# M460 register map
File version: 1.0
Registers are 32-bit, read-write, reset 0x0 unless marked. A register's access mark holds for its fields unless they carry their own. Offsets are from the block's base; [hi:lo] are bit positions.

## SYS (part 2 of 2) — SYS Register Map
Base 0x40000000
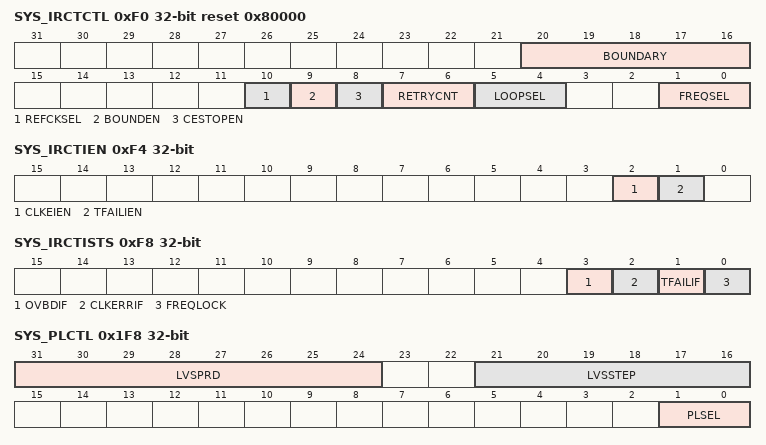
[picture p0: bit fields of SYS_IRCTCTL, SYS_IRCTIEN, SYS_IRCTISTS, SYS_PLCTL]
0xF0 SYS_IRCTCTL reset 0x80000 — HIRC Trim Control Register
  [20:16] BOUNDARY — Boundary Selection. Fill the boundary range from 0x1 to 0x31, 0x0 is reserved. Note: This field is effective only when the BOUNDEN(SYS_IRCTCTL[9]) is enabled.
  [10] REFCKSEL — Reference Clock Selection. Note: HIRC trim reference clock is 20 kHz in test mode.
    0=HIRC trim reference clock is from LXT (32.768 kHz); 1=HIRC trim reference clock is from internal USB synchronous mode
  [9] BOUNDEN — Boundary Enable Bit
    0=Boundary function Disabled; 1=Boundary function Enabled
  [8] CESTOPEN — Clock Error Stop Enable Bit
    0=The trim operation is keep going if clock is inaccuracy; 1=The trim operation is stopped if clock is inaccuracy
  [7:6] RETRYCNT — Trim Value Update Limitation Count. This field defines that how many times the auto trim circuit will try to update the HIRC trim value before the frequency of HIRC locked. Once the HIRC locked, the internal trim value update counter will be reset. If the trim value update counter reached this limitation value and frequency of HIRC still doesn't lock, the auto trim operation will be disabled and FREQSEL will be cleared to 00.
    0=Trim retry count limitation is 64 loops; 1=Trim retry count limitation is 128 loops; 2=Trim retry count limitation is 256 loops; 3=Trim retry count limitation is 512 loops
  [5:4] LOOPSEL — Trim Calculation Loop Selection. This field defines that trim value calculation is based on how many reference clocks. Note: For example, if LOOPSEL is set as 00, auto trim circuit will calculate trim value based on the average frequency difference in 4 clocks of reference clock.
    0=Trim value calculation is based on average difference in 4 clocks of reference clock; 1=Trim value calculation is based on average difference in 8 clocks of reference clock; 2=Trim value calculation is based on average difference in 16 clocks of reference clock; 3=Trim value calculation is based on average difference in 32 clocks of reference clock
  [1:0] FREQSEL — Trim Frequency Selection. This field indicates the target frequency of 12 MHz internal high speed RC oscillator (HIRC) auto trim. During auto trim operation, if clock error detected with CESTOPEN is set to 1 or trim retry limitation count reached, this field will be cleared to 00 automatically.
    0=Disable HIRC auto trim function; 1=Enable HIRC auto trim function and trim HIRC to 12 MHz
0xF4 SYS_IRCTIEN — HIRC Trim Interrupt Enable Register
  [2] CLKEIEN — Clock Error Interrupt Enable Bit. This bit controls if CPU would get an interrupt while clock is inaccuracy during auto trim operation. If this bit is set to1, and CLKERRIF(SYS_IRCTISTS[2]) is set during auto trim operation, an interrupt will be triggered to notify the clock frequency is inaccuracy.
    0=Disable CLKERRIF(SYS_IRCTISTS[2]) status to trigger an interrupt to CPU; 1=Enable CLKERRIF(SYS_IRCTISTS[2]) status to trigger an interrupt to CPU
  [1] TFAILIEN — Trim Failure Interrupt Enable Bit. This bit controls if an interrupt will be triggered while HIRC trim value update limitation count reached and HIRC frequency still not locked on target frequency set by FREQSEL(SYS_IRCTCTL[1:0]). If this bit is high and TFAILIF(SYS_IRCTISTS[1]) is set during auto trim operation, an interrupt will be triggered to notify that HIRC trim value update limitation count was reached.
    0=Disable TFAILIF(SYS_IRCTISTS[1]) status to trigger an interrupt to CPU; 1=Enable TFAILIF(SYS_IRCTISTS[1]) status to trigger an interrupt to CPU
0xF8 SYS_IRCTISTS — HIRC Trim Interrupt Status Register
  [3] OVBDIF — Over Boundary Status. When the over boundary function is set, if there occurs the over boundary condition, this flag will be set. Note: Write 1 to clear this flag.
    0=Over boundary condition did not occur; 1=Over boundary condition occurred
  [2] CLKERRIF — Clock Error Interrupt Status. When the frequency of 32.768 kHz external low speed crystal oscillator (LXT) or 12 MHz internal high speed RC oscillator (HIRC) is shift larger to unreasonable value, this bit will be set and to be an indicate that clock frequency is inaccuracy. Once this bit is set to 1, the auto trim operation stopped and FREQSEL(SYS_IRCTCTL[1:0]) will be cleared to 00 by hardware automatically if CESTOPEN(SYS_IRCTCTL[8]) is set to 1. If this bit is set and CLKEIEN(SYS_IRCTIEN[2]) is high, an interrupt will be triggered to notify the clock frequency is inaccuracy. Write 1 to clear this to 0.
    0=Clock frequency is accuracy; 1=Clock frequency is inaccuracy
  [1] TFAILIF — Trim Failure Interrupt Status. This bit indicates that HIRC trim value update limitation count reached and the HIRC clock frequency still doesn't be locked. Once this bit is set, the auto trim operation stopped and FREQSEL(SYS_IRCTCTL[1:0]) will be cleared to 00 by hardware automatically. If this bit is set and TFAILIEN(SYS_IRCTIEN[1]) is high, an interrupt will be triggered to notify that HIRC trim value update limitation count was reached. Write 1 to clear this to 0.
    0=Trim value update limitation count does not reach; 1=Trim value update limitation count reached and HIRC frequency still not locked
  [0] FREQLOCK — HIRC Frequency Lock Status. This bit indicates the HIRC frequency is locked. This is a status bit and doesn't trigger any interrupt. Write 1 to clear this to 0. This bit will be set automatically, if the frequency is lock and the RC_TRIM is enabled.
    0=The internal high-speed oscillator frequency doesn't lock at 12 MHz yet; 1=The internal high-speed oscillator frequency locked at 12 MHz
0x100 SYS_REGLCTL — Register Lock Control Register
  [7:0] REGLCTL wo — Register Lock Control Code (Write Only). Some registers have write-protection function. Writing these registers have to disable the protected function by writing the sequence value '59h', '16h', '88h' to this field. After this sequence is completed, the REGLCTL bit will be set to 1 and write-protection registers can be normal write. . REGLCTL[0]. Register Lock Control Disable Index (Read Only)
    0=Write-protection Enabled for writing protected registers. Any write to the protected register is ignored; 1=Write-protection Disabled for writing protected registers
0x1EC SYS_PORDISAN — Analog POR Disable Control Register
  [15:0] POROFFAN — Power-on Reset Enable Bit (Write Protect). After powered on, User can turn off internal analog POR circuit to save power by writing 0x5AA5 to this field. The analog POR circuit will be active again when this field is set to another value or chip is reset by other reset source, including: nRESET, Watchdog, LVR reset, BOD reset, ICE reset command and the software-chip reset function. Note: These bits are write protected. Refer to the SYS_REGLCTL register.
0x1F4 SYS_CSERVER ro (reset mask 0xFFFFFF00) — Chip Series Version Register
  [7:0] VERSION — Chip Series Version (Read Only). These bits indicate the series version of chip.
    2=M46xxI/M46xxJ; 3=M46xxG
0x1F8 SYS_PLCTL — Power Level Control Register
  [31:24] LVSPRD — LDO Voltage Scaling Period (Write Protect). The LVSPRD value is the period of each LDO voltage rising step. Note: These bits are write protected. Refer to the SYS_REGLCTL register.
  [21:16] LVSSTEP — LDO Voltage Scaling Step (Write Protect). The LVSSTEP value is LDO voltage rising step. Note: These bits are write protected. Refer to the SYS_REGLCTL register.
  [1:0] PLSEL — Power Level Select (Write Protect). These bits indicate the status of power level. Note: These bits are write protected. Refer to the SYS_REGLCTL register.
    0=Power level is PL0; 1=Power level is PL1
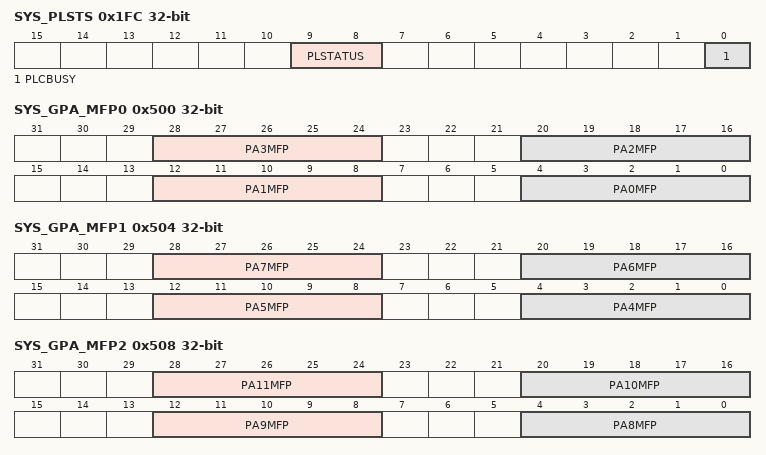
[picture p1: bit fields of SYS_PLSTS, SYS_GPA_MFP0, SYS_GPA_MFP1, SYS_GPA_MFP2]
0x1FC SYS_PLSTS ro — Power Level Status Register
  [9:8] PLSTATUS — Power Level Status (Read Only). This bit indicates the status of power level.
    0=Power level is PL0; 1=Power level is PL1
  [0] PLCBUSY — Power Level Change Busy Bit (Read Only). This bit is set by hardware when power level is changing. After power level change is completed, this bit will be cleared automatically by hardware.
    0=Core voltage change is completed; 1=Core voltage change is ongoing
0x400 SYS_AHBMCTL reset 0x1 — AHB Bus Matrix Priority Control Register
  [0] INTACTEN — Highest AHB Bus Priority of Cortex-M4 Core Enable Bit (Write Protect). Enable Cortex-M4 Core with Highest AHB Bus Priority in AHB Bus Matrix. Note: This bit is write protected. Refer to the SYS_REGLCTL register.
    0=Round-robin mode; 1=Cortex-M4 CPU with highest bus priority when interrupt occurred
0x500 SYS_GPA_MFP0 — GPIOA Multiple Function Control Register 0
  [28:24] PA3MFP — PA.3 Multi-function Pin Selection
    2=SPIM_SS; 3=QSPI0_SS; 4=SPI0_SS; 5=SD1_DAT3; 6=SC0_PWR; 7=UART4_TXD; 8=UART1_TXD; 9=I2C1_SCL; 10=I2C0_SMBAL; 12=BPWM0_CH3; 13=EPWM0_CH2; 14=QEI0_B; 15=EPWM1_BRAKE1; 17=PSIO0_CH4
  [20:16] PA2MFP — PA.2 Multi-function Pin Selection
    2=SPIM_CLK; 3=QSPI0_CLK; 4=SPI0_CLK; 5=SD1_DAT2; 6=SC0_RST; 7=UART4_RXD; 8=UART1_RXD; 9=I2C1_SDA; 10=I2C0_SMBSUS; 12=BPWM0_CH2; 13=EPWM0_CH3; 14=QEI3_INDEX; 17=PSIO0_CH5
  [12:8] PA1MFP — PA.1 Multi-function Pin Selection
    2=SPIM_MISO; 3=QSPI0_MISO0; 4=SPI0_MISO; 5=SD1_DAT1; 6=SC0_DAT; 7=UART0_TXD; 8=UART1_nCTS; 9=I2C2_SCL; 10=CCAP_DATA7; 12=BPWM0_CH1; 13=EPWM0_CH4; 14=QEI3_A; 15=DAC1_ST; 17=PSIO0_CH6
  [4:0] PA0MFP — PA.0 Multi-function Pin Selection
    2=SPIM_MOSI; 3=QSPI0_MOSI0; 4=SPI0_MOSI; 5=SD1_DAT0; 6=SC0_CLK; 7=UART0_RXD; 8=UART1_nRTS; 9=I2C2_SDA; 10=CCAP_DATA6; 12=BPWM0_CH0; 13=EPWM0_CH5; 14=QEI3_B; 15=DAC0_ST; 17=PSIO0_CH7
0x504 SYS_GPA_MFP1 — GPIOA Multiple Function Control Register 1
  [28:24] PA7MFP — PA.7 Multi-function Pin Selection
    2=EBI_AD7; 3=EMAC_RMII_CRSDV; 4=SPI1_CLK; 6=SC2_DAT; 7=UART0_TXD; 8=I2C1_SCL; 9=QSPI1_MISO1; 11=EPWM1_CH4; 12=BPWM1_CH2; 13=ACMP0_WLAT; 14=TM2; 15=INT1; 17=SPI5_SS; 18=KPI_COL1; 19=SPI6_SS
  [20:16] PA6MFP — PA.6 Multi-function Pin Selection
    2=EBI_AD6; 3=EMAC_RMII_RXERR; 4=SPI1_SS; 5=SD1_nCD; 6=SC2_CLK; 7=UART0_RXD; 8=I2C1_SDA; 9=QSPI1_MOSI1; 11=EPWM1_CH5; 12=BPWM1_CH3; 13=ACMP1_WLAT; 14=TM3; 15=INT0; 17=SPI5_CLK; 18=KPI_COL0; 19=SPI6_CLK
  [12:8] PA5MFP — PA.5 Multi-function Pin Selection
    2=SPIM_D2; 3=QSPI0_MISO1; 4=SPI1_I2SMCLK; 5=SD1_CMD; 6=SC2_nCD; 7=UART0_nCTS; 8=UART5_TXD; 9=I2C0_SCL; 10=CAN0_TXD; 11=UART0_TXD; 12=BPWM0_CH5; 13=EPWM0_CH0; 14=QEI0_INDEX
  [4:0] PA4MFP — PA.4 Multi-function Pin Selection
    2=SPIM_D3; 3=QSPI0_MOSI1; 4=SPI0_I2SMCLK; 5=SD1_CLK; 6=SC0_nCD; 7=UART0_nRTS; 8=UART5_RXD; 9=I2C0_SDA; 10=CAN0_RXD; 11=UART0_RXD; 12=BPWM0_CH4; 13=EPWM0_CH1; 14=QEI0_A
0x508 SYS_GPA_MFP2 — GPIOA Multiple Function Control Register 2
  [28:24] PA11MFP — PA.11 Multi-function Pin Selection
    1=EADC1_CH7, EADC2_CH7, ACMP0_P0; 2=EBI_nRD; 3=SC2_PWR; 4=SPI2_SS; 5=SD1_DAT3; 6=USCI0_CLK; 7=I2C2_SCL; 8=UART6_TXD; 9=BPWM0_CH0; 10=EPWM0_SYNC_OUT; 12=I2S1_BCLK; 13=TM0_EXT; 14=DAC1_ST; 18=KPI_ROW4
  [20:16] PA10MFP — PA.10 Multi-function Pin Selection
    1=EADC1_CH6, EADC2_CH6, ACMP1_P0; 2=EBI_nWR; 3=SC2_RST; 4=SPI2_CLK; 5=SD1_DAT2; 6=USCI0_DAT0; 7=I2C2_SDA; 8=UART6_RXD; 9=BPWM0_CH1; 10=QEI1_INDEX; 11=ECAP0_IC0; 12=I2S1_MCLK; 13=TM1_EXT; 14=DAC0_ST; 15=SWDH_CLK; 18=KPI_ROW5
  [12:8] PA9MFP — PA.9 Multi-function Pin Selection
    1=EADC1_CH5, EADC2_CH5; 2=EBI_MCLK; 3=SC2_DAT; 4=SPI2_MISO; 5=SD1_DAT1; 6=USCI0_DAT1; 7=UART1_TXD; 8=UART7_TXD; 9=BPWM0_CH2; 10=QEI1_A; 11=ECAP0_IC1; 12=I2S1_DI; 13=TM2_EXT; 15=SWDH_DAT
  [4:0] PA8MFP — PA.8 Multi-function Pin Selection
    1=EADC1_CH4, EADC2_CH4; 2=EBI_ALE; 3=SC2_CLK; 4=SPI2_MOSI; 5=SD1_DAT0; 6=USCI0_CTL1; 7=UART1_RXD; 8=UART7_RXD; 9=BPWM0_CH3; 10=QEI1_B; 11=ECAP0_IC2; 12=I2S1_DO; 13=TM3_EXT; 15=INT4
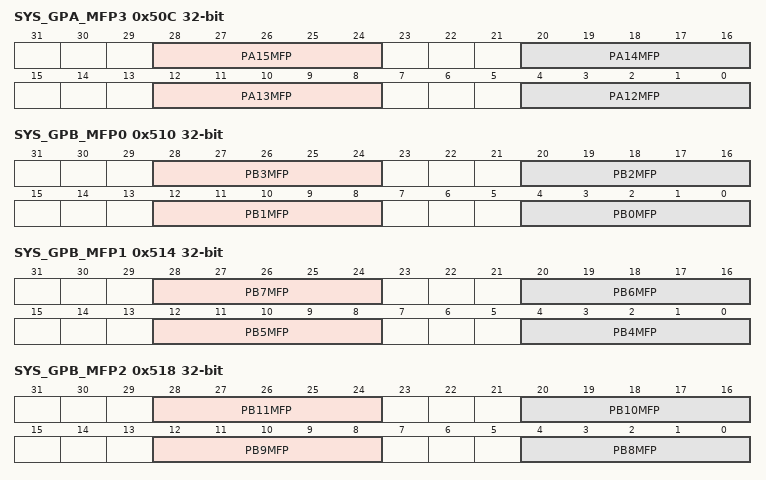
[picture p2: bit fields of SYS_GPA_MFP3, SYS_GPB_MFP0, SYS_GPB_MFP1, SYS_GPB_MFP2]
0x50C SYS_GPA_MFP3 — GPIOA Multiple Function Control Register 3
  [28:24] PA15MFP — PA.15 Multi-function Pin Selection
    2=I2S0_DO; 3=UART0_RXD; 4=SPIM_MOSI; 5=SPI2_MOSI; 6=I2C2_SDA; 7=SC2_CLK; 9=SPI0_MOSI; 11=BPWM1_CH5; 12=EPWM0_SYNC_IN; 13=QEI3_INDEX; 14=USB_OTG_ID; 16=I2C0_SDA; 17=PSIO0_CH7; 19=SPI10_MOSI
  [20:16] PA14MFP — PA.14 Multi-function Pin Selection
    2=I2S0_DI; 3=UART0_TXD; 4=EBI_AD5; 5=SPI2_MISO; 6=I2C2_SCL; 7=SC2_DAT; 9=SPI0_MISO; 11=BPWM1_CH4; 12=QEI1_B; 13=ECAP3_IC2; 14=USB_D+; 16=I2C0_SCL; 17=PSIO0_CH6; 19=SPI10_MISO
  [12:8] PA13MFP — PA.13 Multi-function Pin Selection
    2=I2S0_MCLK; 3=UART4_RXD; 4=I2C1_SDA; 5=SPI2_CLK; 6=CAN0_RXD; 7=SC2_RST; 9=SPI0_CLK; 10=QSPI1_MOSI0; 11=BPWM1_CH3; 12=QEI1_A; 13=ECAP3_IC1; 14=USB_D-; 17=PSIO0_CH5; 19=SPI10_CLK
  [4:0] PA12MFP — PA.12 Multi-function Pin Selection
    2=I2S0_BCLK; 3=UART4_TXD; 4=I2C1_SCL; 5=SPI2_SS; 6=CAN0_TXD; 7=SC2_PWR; 8=SD1_nCD; 9=SPI0_SS; 10=QSPI1_MISO0; 11=BPWM1_CH2; 12=QEI1_INDEX; 13=ECAP3_IC0; 14=USB_VBUS; 17=PSIO0_CH4; 19=SPI10_SS
0x510 SYS_GPB_MFP0 — GPIOB Multiple Function Control Register 0
  [28:24] PB3MFP — PB.3 Multi-function Pin Selection
    1=EADC0_CH3, EADC1_CH11, ACMP0_N; 2=EBI_ADR2; 3=SD0_DAT1; 4=EMAC_RMII_RXD1; 5=SPI1_CLK; 6=UART1_TXD; 7=UART5_nRTS; 9=SC0_RST; 10=I2S0_DI; 11=EPWM0_CH2; 12=I2C1_SCL; 14=TM2; 15=INT2; 17=PSIO0_CH6; 18=KPI_ROW0; 19=SPI4_SS
  [20:16] PB2MFP — PB.2 Multi-function Pin Selection
    1=EADC0_CH2, EADC1_CH10, ACMP0_P1; 2=EBI_ADR3; 3=SD0_DAT0; 4=EMAC_RMII_CRSDV; 5=SPI1_SS; 6=UART1_RXD; 7=UART5_nCTS; 9=SC0_PWR; 10=I2S0_DO; 11=EPWM0_CH3; 12=I2C1_SDA; 14=TM3; 15=INT3; 17=PSIO0_CH7; 18=KPI_ROW1; 19=SPI4_CLK
  [12:8] PB1MFP — PB.1 Multi-function Pin Selection
    1=EADC0_CH1, EADC1_CH9, EADC2_CH9, ACMP3_P0; 2=EBI_ADR8; 3=SD0_CLK; 4=EMAC_RMII_RXERR; 5=SPI1_I2SMCLK; 6=SPI3_I2SMCLK; 7=UART2_TXD; 9=I2C1_SCL; 10=I2S0_LRCK; 11=EPWM0_CH4; 12=EPWM1_CH4; 13=EPWM0_BRAKE0; 14=ACMP2_O; 15=QSPI0_MISO1; 18=KPI_ROW2; 19=SPI4_MISO
  [4:0] PB0MFP — PB.0 Multi-function Pin Selection
    1=EADC0_CH0, EADC1_CH8, EADC2_CH8, ACMP3_N; 2=EBI_ADR9; 3=SD0_CMD; 4=SPI2_I2SMCLK; 6=USCI0_CTL0; 7=UART2_RXD; 8=SPI0_I2SMCLK; 9=I2C1_SDA; 10=I2S1_LRCK; 11=EPWM0_CH5; 12=EPWM1_CH5; 13=EPWM0_BRAKE1; 14=ACMP3_O; 15=QSPI0_MOSI1; 18=KPI_ROW3; 19=SPI4_MOSI
0x514 SYS_GPB_MFP1 — GPIOB Multiple Function Control Register 1
  [28:24] PB7MFP — PB.7 Multi-function Pin Selection
    1=EADC0_CH7, EADC2_CH15, ACMP2_P0; 2=EBI_nWRL; 3=EMAC_RMII_TXEN; 5=CAN1_TXD; 6=UART1_TXD; 7=SD1_CMD; 8=EBI_nCS0; 10=BPWM1_CH4; 11=EPWM1_BRAKE0; 12=EPWM1_CH4; 13=INT5; 14=USB_VBUS_ST; 15=ACMP0_O; 16=SPI3_MISO; 18=KPI_COL4; 19=SPI1_CLK
  [20:16] PB6MFP — PB.6 Multi-function Pin Selection
    1=EADC0_CH6, EADC2_CH14, ACMP2_N; 2=EBI_nWRH; 3=EMAC_PPS; 5=CAN1_RXD; 6=UART1_RXD; 7=SD1_CLK; 8=EBI_nCS1; 10=BPWM1_CH5; 11=EPWM1_BRAKE1; 12=EPWM1_CH5; 13=INT4; 14=USB_VBUS_EN; 15=ACMP1_O; 16=SPI3_MOSI; 18=KPI_COL5; 19=SPI1_SS
  [12:8] PB5MFP — PB.5 Multi-function Pin Selection
    1=EADC0_CH5, ACMP1_N; 2=EBI_ADR0; 3=SD0_DAT3; 4=EMAC_RMII_REFCLK; 5=SPI1_MISO; 6=I2C0_SCL; 7=UART5_TXD; 9=SC0_CLK; 10=I2S0_BCLK; 11=EPWM0_CH0; 12=UART2_TXD; 14=TM0; 15=INT0; 17=PSIO0_CH4; 18=KPI_COL6
  [4:0] PB4MFP — PB.4 Multi-function Pin Selection
    1=EADC0_CH4, ACMP1_P1; 2=EBI_ADR1; 3=SD0_DAT2; 4=EMAC_RMII_RXD0; 5=SPI1_MOSI; 6=I2C0_SDA; 7=UART5_RXD; 9=SC0_DAT; 10=I2S0_MCLK; 11=EPWM0_CH1; 12=UART2_RXD; 14=TM1; 15=INT1; 17=PSIO0_CH5; 18=KPI_COL7
0x518 SYS_GPB_MFP2 — GPIOB Multiple Function Control Register 2
  [28:24] PB11MFP — PB.11 Multi-function Pin Selection
    1=EADC0_CH11; 2=EBI_ADR16; 3=EMAC_RMII_MDC; 5=UART0_nCTS; 6=UART4_TXD; 7=I2C1_SCL; 8=CAN0_TXD; 9=SPI0_I2SMCLK; 10=BPWM1_CH0; 11=SPI3_CLK; 12=CCAP_SFIELD; 14=HSUSB_VBUS_ST
  [20:16] PB10MFP — PB.10 Multi-function Pin Selection
    1=EADC0_CH10, ACMP2_P3; 2=EBI_ADR17; 3=EMAC_RMII_MDIO; 5=UART0_nRTS; 6=UART4_RXD; 7=I2C1_SDA; 8=CAN0_RXD; 10=BPWM1_CH1; 11=SPI3_SS; 12=CCAP_VSYNC; 14=HSUSB_VBUS_EN
  [12:8] PB9MFP — PB.9 Multi-function Pin Selection
    1=EADC0_CH9, ACMP2_P2; 2=EBI_ADR18; 3=EMAC_RMII_TXD0; 5=UART0_TXD; 6=UART1_nCTS; 7=I2C1_SMBAL; 8=UART7_TXD; 9=I2C0_SCL; 10=BPWM1_CH2; 11=SPI3_MISO; 12=CAN2_TXD; 13=INT7; 14=CCAP_HSYNC
  [4:0] PB8MFP — PB.8 Multi-function Pin Selection
    1=EADC0_CH8, ACMP2_P1; 2=EBI_ADR19; 3=EMAC_RMII_TXD1; 5=UART0_RXD; 6=UART1_nRTS; 7=I2C1_SMBSUS; 8=UART7_RXD; 9=I2C0_SDA; 10=BPWM1_CH3; 11=SPI3_MOSI; 12=CAN2_RXD; 13=INT6; 14=EADC2_ST
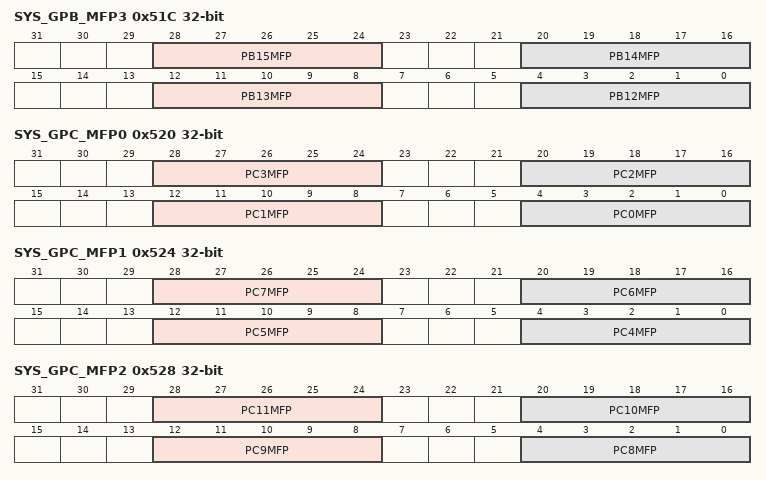
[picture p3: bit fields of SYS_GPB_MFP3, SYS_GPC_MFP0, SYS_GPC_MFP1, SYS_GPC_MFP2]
0x51C SYS_GPB_MFP3 — GPIOB Multiple Function Control Register 3
  [28:24] PB15MFP — PB.15 Multi-function Pin Selection
    1=EADC0_CH15, EADC1_CH15; 2=EBI_AD12; 3=SC1_PWR; 4=SPI0_SS; 5=USCI0_CTL1; 6=UART0_nCTS; 7=UART3_TXD; 8=I2C2_SMBAL; 9=CCAP_DATA1; 10=EPWM0_BRAKE1; 11=EPWM1_CH0; 12=ETMC_TRACE_DATA0; 13=TM0_EXT; 14=USB_VBUS_EN; 15=HSUSB_VBUS_EN; 17=PSIO0_CH0; 18=KPI_COL0; 19=SPI9_CLK
  [20:16] PB14MFP — PB.14 Multi-function Pin Selection
    1=EADC0_CH14, EADC1_CH14; 2=EBI_AD13; 3=SC1_RST; 4=SPI0_CLK; 5=USCI0_DAT1; 6=UART0_nRTS; 7=UART3_RXD; 8=I2C2_SMBSUS; 9=CCAP_DATA0; 11=EPWM1_CH1; 12=ETMC_TRACE_DATA1; 13=TM1_EXT; 14=CLKO; 15=USB_VBUS_ST; 17=PSIO0_CH1; 18=KPI_COL1; 19=SPI9_SS
  [12:8] PB13MFP — PB.13 Multi-function Pin Selection
    1=EADC0_CH13, EADC1_CH13, DAC1_OUT, ACMP0_P3, ACMP1_P3; 2=EBI_AD14; 3=SC1_DAT; 4=SPI0_MISO; 5=USCI0_DAT0; 6=UART0_TXD; 7=UART3_nRTS; 8=I2C2_SCL; 10=CCAP_PIXCLK; 11=EPWM1_CH2; 12=ETMC_TRACE_DATA2; 13=TM2_EXT; 14=CAN3_TXD; 16=SPI3_CLK; 17=PSIO0_CH2; 18=KPI_COL2; 19=SPI9_MISO
  [4:0] PB12MFP — PB.12 Multi-function Pin Selection
    1=EADC0_CH12, EADC1_CH12, DAC0_OUT, ACMP0_P2, ACMP1_P2; 2=EBI_AD15; 3=SC1_CLK; 4=SPI0_MOSI; 5=USCI0_CLK; 6=UART0_RXD; 7=UART3_nCTS; 8=I2C2_SDA; 9=SD0_nCD; 10=CCAP_SCLK; 11=EPWM1_CH3; 12=ETMC_TRACE_DATA3; 13=TM3_EXT; 14=CAN3_RXD; 16=SPI3_SS; 17=PSIO0_CH3; 18=KPI_COL3
0x520 SYS_GPC_MFP0 — GPIOC Multiple Function Control Register 0
  [28:24] PC3MFP — PC.3 Multi-function Pin Selection
    2=EBI_AD3; 3=SPIM_SS; 4=QSPI0_SS; 5=SC1_PWR; 6=I2S0_MCLK; 7=SPI1_MISO; 8=UART2_nRTS; 9=I2C0_SMBAL; 10=CAN1_TXD; 11=UART3_TXD; 12=EPWM1_CH2; 13=CCAP_DATA3; 14=QSPI1_MISO0; 15=I2C3_SCL; 16=HBI_nCS; 17=PSIO0_CH2; 18=KPI_ROW2; 19=SPI7_SS
  [20:16] PC2MFP — PC.2 Multi-function Pin Selection
    2=EBI_AD2; 3=SPIM_CLK; 4=QSPI0_CLK; 5=SC1_RST; 6=I2S0_DI; 7=SPI1_MOSI; 8=UART2_nCTS; 9=I2C0_SMBSUS; 10=CAN1_RXD; 11=UART3_RXD; 12=EPWM1_CH3; 13=CCAP_DATA2; 14=QSPI1_MOSI0; 15=I2C3_SDA; 16=HBI_nRESET; 17=PSIO0_CH3; 18=KPI_ROW3; 19=SPI7_CLK
  [12:8] PC1MFP — PC.1 Multi-function Pin Selection
    2=EBI_AD1; 3=SPIM_MISO; 4=QSPI0_MISO0; 5=SC1_DAT; 6=I2S0_DO; 7=SPI1_CLK; 8=UART2_TXD; 9=I2C0_SCL; 10=CAN2_TXD; 12=EPWM1_CH4; 13=CCAP_DATA1; 14=ACMP0_O; 15=EADC0_ST; 16=HBI_RWDS; 17=QSPI1_SS; 18=KPI_ROW4; 19=SPI7_MISO
  [4:0] PC0MFP — PC.0 Multi-function Pin Selection
    2=EBI_AD0; 3=SPIM_MOSI; 4=QSPI0_MOSI0; 5=SC1_CLK; 6=I2S0_LRCK; 7=SPI1_SS; 8=UART2_RXD; 9=I2C0_SDA; 10=CAN2_RXD; 12=EPWM1_CH5; 13=CCAP_DATA0; 14=ACMP1_O; 15=EADC1_ST; 16=HBI_D2; 17=QSPI1_CLK; 18=KPI_ROW5; 19=SPI7_MOSI
0x524 SYS_GPC_MFP1 — GPIOC Multiple Function Control Register 1
  [28:24] PC7MFP — PC.7 Multi-function Pin Selection
    2=EBI_AD9; 3=EMAC_RMII_RXD0; 4=SPI1_MISO; 5=UART4_TXD; 6=SC2_PWR; 7=UART0_nCTS; 8=I2C1_SMBAL; 9=UART6_TXD; 10=ACMP2_WLAT; 11=EPWM1_CH2; 12=BPWM1_CH0; 13=CAN3_TXD; 14=TM0; 15=INT3; 18=KPI_COL3; 19=SPI6_MISO
  [20:16] PC6MFP — PC.6 Multi-function Pin Selection
    2=EBI_AD8; 3=EMAC_RMII_RXD1; 4=SPI1_MOSI; 5=UART4_RXD; 6=SC2_RST; 7=UART0_nRTS; 8=I2C1_SMBSUS; 9=UART6_RXD; 10=ACMP3_WLAT; 11=EPWM1_CH3; 12=BPWM1_CH1; 13=CAN3_RXD; 14=TM1; 15=INT2; 18=KPI_COL2; 19=SPI6_MOSI
  [12:8] PC5MFP — PC.5 Multi-function Pin Selection
    2=EBI_AD5; 3=SPIM_D2; 4=QSPI0_MISO1; 8=UART2_TXD; 9=I2C1_SCL; 10=CAN0_TXD; 11=UART4_TXD; 12=EPWM1_CH0; 13=CCAP_DATA5; 14=QSPI1_SS; 15=I2C3_SMBAL; 16=HBI_nCK; 17=PSIO0_CH0; 18=KPI_ROW0
  [4:0] PC4MFP — PC.4 Multi-function Pin Selection
    2=EBI_AD4; 3=SPIM_D3; 4=QSPI0_MOSI1; 5=SC1_nCD; 6=I2S0_BCLK; 7=SPI1_I2SMCLK; 8=UART2_RXD; 9=I2C1_SDA; 10=CAN0_RXD; 11=UART4_RXD; 12=EPWM1_CH1; 13=CCAP_DATA4; 14=QSPI1_CLK; 15=I2C3_SMBSUS; 16=HBI_CK; 17=PSIO0_CH1; 18=KPI_ROW1
0x528 SYS_GPC_MFP2 — GPIOC Multiple Function Control Register 2
  [28:24] PC11MFP — PC.11 Multi-function Pin Selection
    1=EADC2_CH12, ACMP3_P3; 2=EBI_ADR5; 3=UART0_RXD; 4=I2C0_SDA; 5=UART6_RXD; 6=SPI3_MOSI; 10=I2C4_SDA; 11=ECAP1_IC1; 12=EPWM1_CH1; 14=ACMP1_O
  [20:16] PC10MFP — PC.10 Multi-function Pin Selection
    1=EADC2_CH11, ACMP3_P2; 2=EBI_ADR6; 5=UART6_nRTS; 6=SPI3_CLK; 7=UART3_TXD; 9=CAN1_TXD; 10=I2C4_SMBAL; 11=ECAP1_IC0; 12=EPWM1_CH2; 14=EADC1_ST
  [12:8] PC9MFP — PC.9 Multi-function Pin Selection
    1=EADC2_CH10, ACMP3_P1; 2=EBI_ADR7; 5=UART6_nCTS; 6=SPI3_SS; 7=UART3_RXD; 9=CAN1_RXD; 10=I2C4_SMBSUS; 12=EPWM1_CH3; 14=EADC1_ST
  [4:0] PC8MFP — PC.8 Multi-function Pin Selection
    2=EBI_ADR16; 3=EMAC_RMII_REFCLK; 4=I2C0_SDA; 5=UART4_nCTS; 8=UART1_RXD; 11=EPWM1_CH1; 12=BPWM1_CH4; 18=KPI_COL4
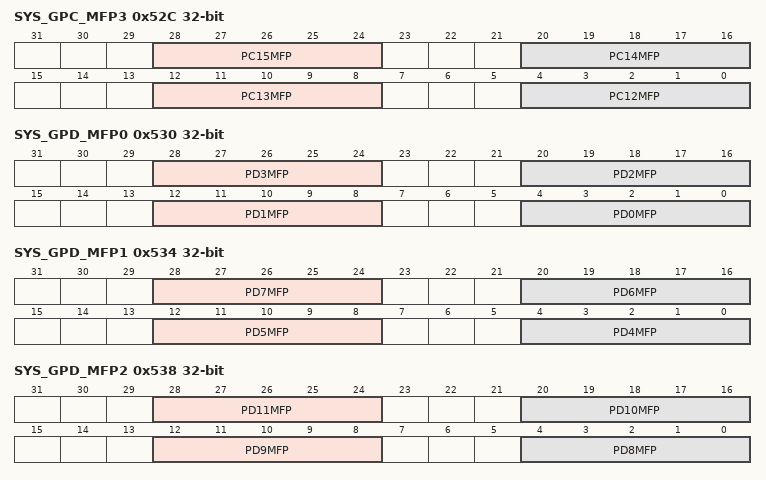
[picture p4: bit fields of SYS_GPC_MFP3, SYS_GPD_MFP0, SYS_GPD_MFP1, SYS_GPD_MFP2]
0x52C SYS_GPC_MFP3 — GPIOC Multiple Function Control Register 3
  [28:24] PC15MFP — PC.15 Multi-function Pin Selection
  [20:16] PC14MFP — PC.14 Multi-function Pin Selection
    2=EBI_AD11; 3=SC1_nCD; 4=SPI0_I2SMCLK; 5=USCI0_CTL0; 6=QSPI0_CLK; 10=ITM_TRACE_SWO; 11=EPWM0_SYNC_IN; 12=ETMC_TRACE_CLK; 13=TM1; 14=USB_VBUS_ST; 15=HSUSB_VBUS_ST; 19=SPI9_MOSI
  [12:8] PC13MFP — PC.13 Multi-function Pin Selection
    1=EADC1_CH3, EADC2_CH3; 2=EBI_ADR10; 3=SC2_nCD; 4=SPI2_I2SMCLK; 5=CAN1_TXD; 6=USCI0_CTL0; 7=UART2_TXD; 8=UART8_nCTS; 9=BPWM0_CH4; 13=CLKO; 14=EADC0_ST; 19=SPI9_SS
  [4:0] PC12MFP — PC.12 Multi-function Pin Selection
    1=EADC2_CH13; 2=EBI_ADR4; 3=UART0_TXD; 4=I2C0_SCL; 5=UART6_TXD; 6=SPI3_MISO; 9=SC0_nCD; 10=I2C4_SCL; 11=ECAP1_IC2; 12=EPWM1_CH0; 14=ACMP0_O
0x530 SYS_GPD_MFP0 — GPIOD Multiple Function Control Register 0
  [28:24] PD3MFP — PD.3 Multi-function Pin Selection
    2=EBI_AD10; 3=USCI0_CTL1; 4=SPI0_SS; 5=UART3_nRTS; 7=SC2_PWR; 8=SC1_nCD; 9=UART0_TXD; 10=I2S1_BCLK; 13=QEI3_A
  [20:16] PD2MFP — PD.2 Multi-function Pin Selection
    2=EBI_AD11; 3=USCI0_DAT1; 4=SPI0_CLK; 5=UART3_nCTS; 7=SC2_RST; 9=UART0_RXD; 10=I2S1_MCLK; 13=QEI3_B
  [12:8] PD1MFP — PD.1 Multi-function Pin Selection
    2=EBI_AD12; 3=USCI0_DAT0; 4=SPI0_MISO; 5=UART3_TXD; 6=I2C2_SCL; 7=SC2_DAT; 10=I2S1_DI; 12=QEI2_INDEX; 13=ECAP2_IC0
  [4:0] PD0MFP — PD.0 Multi-function Pin Selection
    2=EBI_AD13; 3=USCI0_CLK; 4=SPI0_MOSI; 5=UART3_RXD; 6=I2C2_SDA; 7=SC2_CLK; 10=I2S1_DO; 12=QEI2_A; 13=ECAP2_IC1; 14=TM2
0x534 SYS_GPD_MFP1 — GPIOD Multiple Function Control Register 1
  [28:24] PD7MFP — PD.7 Multi-function Pin Selection
    2=EBI_AD4; 3=UART1_TXD; 4=I2C0_SCL; 5=SPI1_MISO; 6=QSPI1_MISO0; 7=CCAP_HSYNC; 8=SC1_PWR; 16=HBI_D5; 17=PSIO0_CH4
  [20:16] PD6MFP — PD.6 Multi-function Pin Selection
    2=EBI_AD5; 3=UART1_RXD; 4=I2C0_SDA; 5=SPI1_MOSI; 6=QSPI1_MOSI0; 8=SC1_RST; 14=ACMP0_O; 15=EADC0_ST; 16=HBI_D6; 17=PSIO0_CH5
  [12:8] PD5MFP — PD.5 Multi-function Pin Selection
    4=I2C1_SCL; 5=SPI1_CLK; 8=SC1_DAT; 14=ACMP1_O; 15=EADC1_ST; 16=HBI_D7; 17=PSIO0_CH6
  [4:0] PD4MFP — PD.4 Multi-function Pin Selection
    3=USCI0_CTL0; 4=I2C1_SDA; 5=SPI1_SS; 8=SC1_CLK; 14=USB_VBUS_ST; 17=PSIO0_CH7
0x538 SYS_GPD_MFP2 — GPIOD Multiple Function Control Register 2
  [28:24] PD11MFP — PD.11 Multi-function Pin Selection
    1=EADC1_CH1, EADC2_CH1; 2=EBI_nCS1; 3=UART1_TXD; 4=CAN0_TXD; 8=UART8_TXD; 10=QEI0_A; 11=ECAP3_IC1; 15=INT6; 19=SPI9_MISO
  [20:16] PD10MFP — PD.10 Multi-function Pin Selection
    1=EADC1_CH0, EADC2_CH0; 2=EBI_nCS2; 3=UART1_RXD; 4=CAN0_RXD; 8=UART8_RXD; 10=QEI0_B; 11=ECAP3_IC2; 15=INT7; 19=SPI9_MOSI
  [12:8] PD9MFP — PD.9 Multi-function Pin Selection
    2=EBI_AD7; 3=I2C2_SCL; 4=UART2_nCTS; 5=UART7_TXD; 6=CAN2_TXD; 17=PSIO0_CH2
  [4:0] PD8MFP — PD.8 Multi-function Pin Selection
    2=EBI_AD6; 3=I2C2_SDA; 4=UART2_nRTS; 5=UART7_RXD; 6=CAN2_RXD; 17=PSIO0_CH3
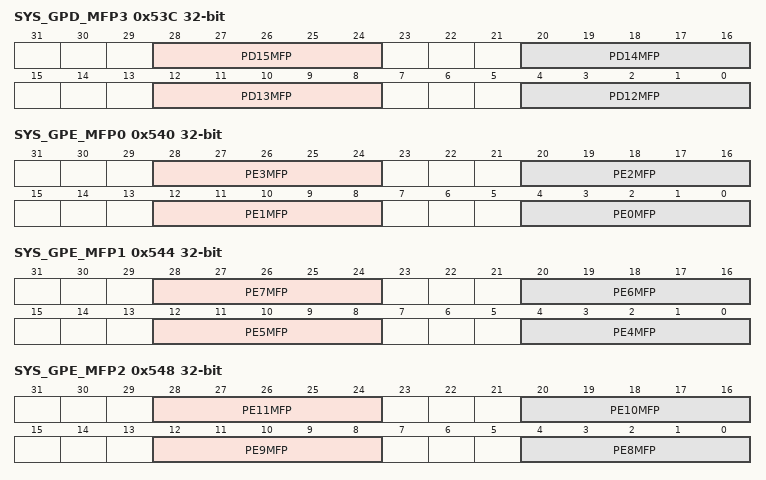
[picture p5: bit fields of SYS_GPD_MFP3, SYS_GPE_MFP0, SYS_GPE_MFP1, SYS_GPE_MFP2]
0x53C SYS_GPD_MFP3 — GPIOD Multiple Function Control Register 3
  [28:24] PD15MFP — PD.15 Multi-function Pin Selection
  [20:16] PD14MFP — PD.14 Multi-function Pin Selection
    2=EBI_nCS0; 3=SPI3_I2SMCLK; 4=SC1_nCD; 5=SPI0_I2SMCLK; 10=I2S1_BCLK; 11=EPWM0_CH4
  [12:8] PD13MFP — PD.13 Multi-function Pin Selection
    2=EBI_AD10; 3=SD0_nCD; 4=SPI0_I2SMCLK; 5=SPI1_I2SMCLK; 6=QSPI1_MOSI0; 7=SC2_nCD; 8=SD1_CLK; 9=UART6_RXD; 10=I2S1_LRCK; 11=BPWM0_CH0; 12=QEI2_B; 13=ECAP2_IC2; 14=CLKO; 15=EADC0_ST; 19=QSPI1_MOSI1
  [4:0] PD12MFP — PD.12 Multi-function Pin Selection
    1=EADC1_CH2, EADC2_CH2; 2=EBI_nCS0; 5=CAN1_RXD; 7=UART2_RXD; 8=UART8_nRTS; 9=BPWM0_CH5; 10=QEI0_INDEX; 11=ECAP3_IC0; 13=CLKO; 14=EADC0_ST; 15=INT5; 19=SPI9_CLK
0x540 SYS_GPE_MFP0 — GPIOE Multiple Function Control Register 0
  [28:24] PE3MFP — PE.3 Multi-function Pin Selection
    2=EBI_MCLK; 3=SD0_DAT1; 4=SPIM_MISO; 5=SPI3_MISO; 6=SC0_DAT; 7=USCI0_DAT0; 8=UART6_nRTS; 9=UART7_TXD; 10=UART8_nCTS; 11=QEI0_A; 12=EPWM0_CH4; 13=BPWM0_CH1
  [20:16] PE2MFP — PE.2 Multi-function Pin Selection
    2=EBI_ALE; 3=SD0_DAT0; 4=SPIM_MOSI; 5=SPI3_MOSI; 6=SC0_CLK; 7=USCI0_CLK; 8=UART6_nCTS; 9=UART7_RXD; 10=UART8_nRTS; 11=QEI0_B; 12=EPWM0_CH5; 13=BPWM0_CH0
  [12:8] PE1MFP — PE.1 Multi-function Pin Selection
    2=EBI_AD10; 3=QSPI0_MISO0; 4=SC2_DAT; 5=I2S0_BCLK; 6=SPI1_MISO; 7=UART3_TXD; 8=I2C1_SCL; 9=UART4_nCTS; 10=UART8_TXD
  [4:0] PE0MFP — PE.0 Multi-function Pin Selection
    2=EBI_AD11; 3=QSPI0_MOSI0; 4=SC2_CLK; 5=I2S0_MCLK; 6=SPI1_MOSI; 7=UART3_RXD; 8=I2C1_SDA; 9=UART4_nRTS; 10=UART8_RXD
0x544 SYS_GPE_MFP1 — GPIOE Multiple Function Control Register 1
  [28:24] PE7MFP — PE.7 Multi-function Pin Selection
    3=SD0_CMD; 4=SPIM_D2; 8=UART5_TXD; 9=CAN1_TXD; 10=UART9_nCTS; 11=QEI1_INDEX; 12=EPWM0_CH0; 13=BPWM0_CH5; 14=ACMP2_O; 17=PSIO0_CH0
  [20:16] PE6MFP — PE.6 Multi-function Pin Selection
    3=SD0_CLK; 4=SPIM_D3; 5=SPI3_I2SMCLK; 6=SC0_nCD; 7=USCI0_CTL0; 8=UART5_RXD; 9=CAN1_RXD; 10=UART9_nRTS; 11=QEI1_A; 12=EPWM0_CH1; 13=BPWM0_CH4; 14=ACMP3_O; 17=PSIO0_CH1
  [12:8] PE5MFP — PE.5 Multi-function Pin Selection
    2=EBI_nRD; 3=SD0_DAT3; 4=SPIM_SS; 5=SPI3_SS; 6=SC0_PWR; 7=USCI0_CTL1; 8=UART6_TXD; 9=UART7_nRTS; 10=UART9_TXD; 11=QEI1_B; 12=EPWM0_CH2; 13=BPWM0_CH3; 17=PSIO0_CH2
  [4:0] PE4MFP — PE.4 Multi-function Pin Selection
    2=EBI_nWR; 3=SD0_DAT2; 4=SPIM_CLK; 5=SPI3_CLK; 6=SC0_RST; 7=USCI0_DAT1; 8=UART6_RXD; 9=UART7_nCTS; 10=UART9_RXD; 11=QEI0_INDEX; 12=EPWM0_CH3; 13=BPWM0_CH2; 17=PSIO0_CH3
0x548 SYS_GPE_MFP2 — GPIOE Multiple Function Control Register 2
  [28:24] PE11MFP — PE.11 Multi-function Pin Selection
    2=EBI_ADR13; 3=EMAC_RMII_TXD1; 4=I2S0_DO; 5=SPI2_SS; 7=UART3_RXD; 8=UART1_nCTS; 10=EPWM0_CH3; 11=EPWM1_BRAKE1; 13=ECAP1_IC2; 14=TRACE_DATA0; 18=KPI_COL7
  [20:16] PE10MFP — PE.10 Multi-function Pin Selection
    2=EBI_ADR12; 3=EMAC_RMII_TXD0; 4=I2S0_DI; 5=SPI2_MOSI; 7=UART3_TXD; 10=EPWM0_CH2; 11=EPWM1_BRAKE0; 12=ECAP0_IC2; 13=QEI2_B; 14=TRACE_DATA1; 15=ECAP3_IC2
  [12:8] PE9MFP — PE.9 Multi-function Pin Selection
    2=EBI_ADR11; 3=EMAC_RMII_MDIO; 4=I2S0_MCLK; 5=SPI2_MISO; 7=UART2_RXD; 10=EPWM0_CH1; 11=EPWM0_BRAKE1; 12=ECAP0_IC1; 13=QEI2_A; 14=TRACE_DATA2; 15=ECAP3_IC1
  [4:0] PE8MFP — PE.8 Multi-function Pin Selection
    2=EBI_ADR10; 3=EMAC_RMII_MDC; 4=I2S0_BCLK; 5=SPI2_CLK; 7=UART2_TXD; 10=EPWM0_CH0; 11=EPWM0_BRAKE0; 12=ECAP0_IC0; 13=QEI2_INDEX; 14=TRACE_DATA3; 15=ECAP3_IC0
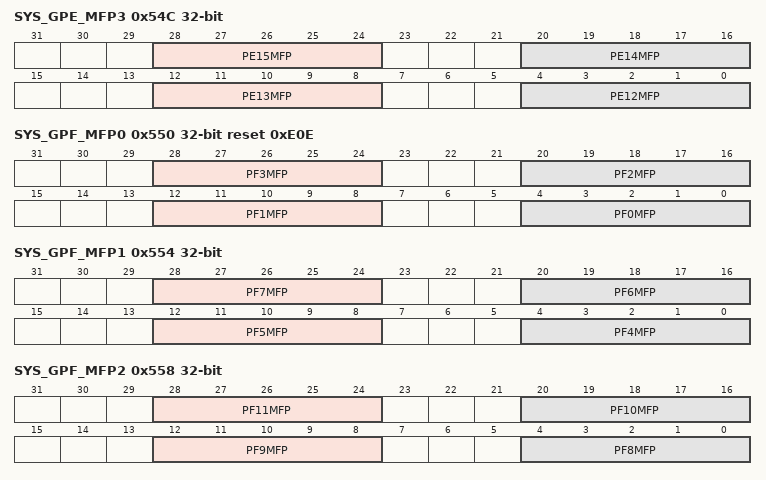
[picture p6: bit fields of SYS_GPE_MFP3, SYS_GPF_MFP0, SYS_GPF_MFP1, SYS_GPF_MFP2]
0x54C SYS_GPE_MFP3 — GPIOE Multiple Function Control Register 3
  [28:24] PE15MFP — PE.15 Multi-function Pin Selection
    2=EBI_AD9; 3=UART2_RXD; 4=CAN0_RXD; 6=UART6_RXD; 17=PSIO0_CH1
  [20:16] PE14MFP — PE.14 Multi-function Pin Selection
    2=EBI_AD8; 3=UART2_TXD; 4=CAN0_TXD; 5=SD1_nCD; 6=UART6_TXD; 17=PSIO0_CH0
  [12:8] PE13MFP — PE.13 Multi-function Pin Selection
    2=EBI_ADR15; 3=EMAC_PPS; 4=I2C0_SCL; 5=UART4_nRTS; 8=UART1_TXD; 10=EPWM0_CH5; 11=EPWM1_CH0; 12=BPWM1_CH5; 13=ECAP1_IC0; 14=ITM_TRACE_SWO; 18=KPI_COL5
  [4:0] PE12MFP — PE.12 Multi-function Pin Selection
    2=EBI_ADR14; 3=EMAC_RMII_TXEN; 4=I2S0_LRCK; 5=SPI2_I2SMCLK; 8=UART1_nRTS; 10=EPWM0_CH4; 13=ECAP1_IC1; 14=TRACE_CLK; 18=KPI_COL6
0x550 SYS_GPF_MFP0 reset 0xE0E — GPIOF Multiple Function Control Register 0
  [28:24] PF3MFP — PF.3 Multi-function Pin Selection
    2=EBI_nCS0; 3=UART0_TXD; 4=I2C0_SCL; 7=UART9_TXD; 10=XT1_IN; 11=BPWM1_CH0; 12=I2C4_SMBAL; 13=ACMP2_O; 15=EADC2_ST
  [20:16] PF2MFP — PF.2 Multi-function Pin Selection
    2=EBI_nCS1; 3=UART0_RXD; 4=I2C0_SDA; 5=QSPI0_CLK; 7=UART9_RXD; 10=XT1_OUT; 11=BPWM1_CH1; 12=I2C4_SMBSUS; 13=ACMP3_O
  [12:8] PF1MFP — PF.1 Multi-function Pin Selection
    2=UART1_RXD; 3=I2C1_SDA; 4=UART0_RXD; 5=SC1_CLK; 6=I2S0_LRCK; 8=UART2_RXD; 9=I2C0_SDA; 10=CAN2_RXD; 11=EPWM1_CH5; 12=BPWM1_CH1; 13=ACMP1_O; 14=ICE_CLK; 15=EADC1_ST; 19=QSPI1_MOSI0
  [4:0] PF0MFP — PF.0 Multi-function Pin Selection
    2=UART1_TXD; 3=I2C1_SCL; 4=UART0_TXD; 5=SC1_DAT; 6=I2S0_DO; 8=UART2_TXD; 9=I2C0_SCL; 10=CAN2_TXD; 11=EPWM1_CH4; 12=BPWM1_CH0; 13=ACMP0_O; 14=ICE_DAT; 15=EADC0_ST; 19=QSPI1_MISO0
0x554 SYS_GPF_MFP1 — GPIOF Multiple Function Control Register 1
  [28:24] PF7MFP — PF.7 Multi-function Pin Selection
    2=EBI_ADR18; 3=SC0_DAT; 4=I2S0_DO; 5=SPI0_MISO; 6=UART4_TXD; 7=CCAP_DATA0; 8=CAN2_TXD; 10=TAMPER1; 19=SPI5_SS
  [20:16] PF6MFP — PF.6 Multi-function Pin Selection
    2=EBI_ADR19; 3=SC0_CLK; 4=I2S0_LRCK; 5=SPI0_MOSI; 6=UART4_RXD; 7=EBI_nCS0; 8=CAN2_RXD; 9=SPI3_I2SMCLK; 10=TAMPER0; 13=QEI2_INDEX; 14=ITM_TRACE_SWO; 19=SPI5_CLK
  [12:8] PF5MFP — PF.5 Multi-function Pin Selection
    2=UART2_RXD; 3=EBI_AD1; 4=UART2_nCTS; 7=EPWM0_CH0; 8=BPWM0_CH4; 9=EPWM0_SYNC_OUT; 10=X32_IN; 11=EADC0_ST; 12=I2C4_SCL; 13=QEI2_A; 19=SPI5_MOSI
  [4:0] PF4MFP — PF.4 Multi-function Pin Selection
    2=UART2_TXD; 3=EBI_AD0; 4=UART2_nRTS; 7=EPWM0_CH1; 8=BPWM0_CH5; 10=X32_OUT; 11=EADC1_ST; 12=I2C4_SDA; 13=QEI2_B; 19=SPI5_MISO
0x558 SYS_GPF_MFP2 — GPIOF Multiple Function Control Register 2
  [28:24] PF11MFP — PF.11 Multi-function Pin Selection
    2=EBI_ADR14; 3=SPI2_MOSI; 6=UART5_TXD; 7=CCAP_DATA4; 8=CAN3_TXD; 10=TAMPER5; 11=UART9_nCTS; 13=TM3
  [20:16] PF10MFP — PF.10 Multi-function Pin Selection
    2=EBI_ADR15; 3=SC0_nCD; 4=I2S0_BCLK; 5=SPI0_I2SMCLK; 6=UART5_RXD; 7=CCAP_DATA3; 8=CAN3_RXD; 10=TAMPER4; 11=UART9_nRTS
  [12:8] PF9MFP — PF.9 Multi-function Pin Selection
    2=EBI_ADR16; 3=SC0_PWR; 4=I2S0_MCLK; 5=SPI0_SS; 6=UART5_nRTS; 7=CCAP_DATA2; 8=CAN1_TXD; 10=TAMPER3; 11=UART9_TXD
  [4:0] PF8MFP — PF.8 Multi-function Pin Selection
    2=EBI_ADR17; 3=SC0_RST; 4=I2S0_DI; 5=SPI0_CLK; 6=UART5_nCTS; 7=CCAP_DATA1; 8=CAN1_RXD; 10=TAMPER2; 11=UART9_RXD
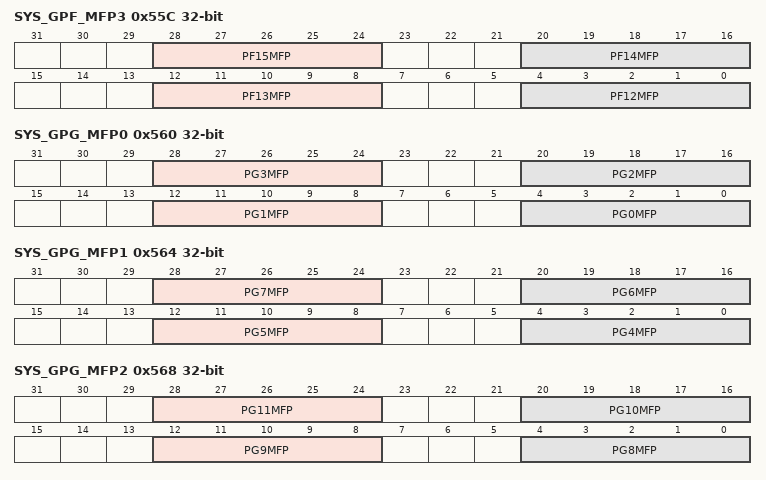
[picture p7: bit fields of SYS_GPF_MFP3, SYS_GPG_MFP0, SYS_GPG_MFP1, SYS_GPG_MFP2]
0x55C SYS_GPF_MFP3 — GPIOF Multiple Function Control Register 3
  [28:24] PF15MFP — PF.15 Multi-function Pin Selection
  [20:16] PF14MFP — PF.14 Multi-function Pin Selection
  [12:8] PF13MFP — PF.13 Multi-function Pin Selection
  [4:0] PF12MFP — PF.12 Multi-function Pin Selection
0x560 SYS_GPG_MFP0 — GPIOG Multiple Function Control Register 0
  [28:24] PG3MFP — PG.3 Multi-function Pin Selection
    2=EBI_ADR12; 3=SPI2_CLK; 4=I2C0_SMBSUS; 5=I2C1_SDA; 7=CCAP_DATA6; 9=I2C3_SMBSUS; 13=TM1
  [20:16] PG2MFP — PG.2 Multi-function Pin Selection
    2=EBI_ADR11; 3=SPI2_SS; 4=I2C0_SMBAL; 5=I2C1_SCL; 7=CCAP_DATA7; 9=I2C3_SMBAL; 13=TM0
  [12:8] PG1MFP — PG.1 Multi-function Pin Selection
    2=EBI_ADR9; 3=SPI2_I2SMCLK; 4=I2C0_SDA; 5=I2C1_SMBSUS; 6=UART2_TXD; 7=CAN1_RXD; 8=UART1_RXD; 9=I2C3_SDA
  [4:0] PG0MFP — PG.0 Multi-function Pin Selection
    2=EBI_ADR8; 4=I2C0_SCL; 5=I2C1_SMBAL; 6=UART2_RXD; 7=CAN1_TXD; 8=UART1_TXD; 9=I2C3_SCL
0x564 SYS_GPG_MFP1 — GPIOG Multiple Function Control Register 1
  [28:24] PG7MFP — PG.7 Multi-function Pin Selection
    2=EBI_nWRL; 3=SPI3_MISO; 4=SC1_DAT; 8=I2C3_SCL; 10=I2S1_DO; 11=EPWM0_CH1
  [20:16] PG6MFP — PG.6 Multi-function Pin Selection
    2=EBI_nCS2; 3=SPI3_CLK; 4=SC1_RST; 8=I2C3_SMBSUS; 10=I2S1_DI; 11=EPWM0_CH2
  [12:8] PG5MFP — PG.5 Multi-function Pin Selection
    2=EBI_nCS1; 3=SPI3_SS; 4=SC1_PWR; 8=I2C3_SMBAL; 10=I2S1_MCLK; 11=EPWM0_CH3
  [4:0] PG4MFP — PG.4 Multi-function Pin Selection
    2=EBI_ADR13; 3=SPI2_MISO; 7=CCAP_DATA5; 13=TM2
0x568 SYS_GPG_MFP2 — GPIOG Multiple Function Control Register 2
  [28:24] PG11MFP — PG.11 Multi-function Pin Selection
    2=EBI_AD2; 3=SD1_DAT1; 4=SPIM_SS; 5=QSPI1_SS; 6=UART7_TXD; 7=CCAP_SFIELD; 8=I2C4_SMBAL; 9=ECAP2_IC2; 12=BPWM0_CH3; 16=HBI_D0; 19=SPI8_MOSI
  [20:16] PG10MFP — PG.10 Multi-function Pin Selection
    2=EBI_AD1; 3=SD1_DAT2; 4=SPIM_D3; 5=QSPI1_MOSI1; 7=CCAP_SCLK; 8=I2C4_SDA; 9=ECAP2_IC1; 12=BPWM0_CH4; 16=HBI_D3; 19=SPI8_CLK
  [12:8] PG9MFP — PG.9 Multi-function Pin Selection
    2=EBI_AD0; 3=SD1_DAT3; 4=SPIM_D2; 5=QSPI1_MISO1; 7=CCAP_PIXCLK; 8=I2C4_SCL; 9=ECAP2_IC0; 12=BPWM0_CH5; 16=HBI_D4; 19=SPI8_SS
  [4:0] PG8MFP — PG.8 Multi-function Pin Selection
    2=EBI_nWRH; 3=SPI3_MOSI; 4=SC1_CLK; 8=I2C3_SDA; 10=I2S1_LRCK; 11=EPWM0_CH0
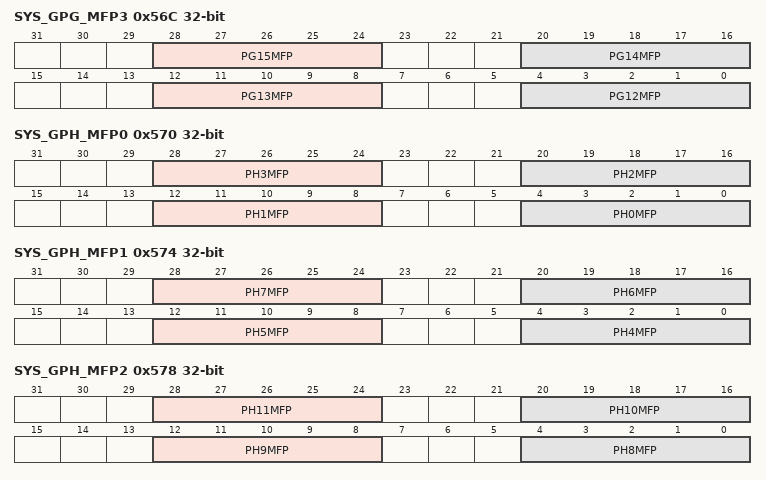
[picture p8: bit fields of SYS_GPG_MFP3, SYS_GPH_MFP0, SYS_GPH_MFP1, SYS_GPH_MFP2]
0x56C SYS_GPG_MFP3 — GPIOG Multiple Function Control Register 3
  [28:24] PG15MFP — PG.15 Multi-function Pin Selection
    3=SD1_nCD; 14=CLKO; 15=EADC0_ST; 16=HBI_D7; 19=QSPI1_MISO1
  [20:16] PG14MFP — PG.14 Multi-function Pin Selection
    2=EBI_AD5; 3=SD1_CLK; 4=SPIM_MOSI; 5=QSPI1_MOSI0; 6=UART6_RXD; 12=BPWM0_CH0; 16=HBI_D6
  [12:8] PG13MFP — PG.13 Multi-function Pin Selection
    2=EBI_AD4; 3=SD1_CMD; 4=SPIM_MISO; 5=QSPI1_MISO0; 6=UART6_TXD; 7=CCAP_HSYNC; 12=BPWM0_CH1; 16=HBI_D5
  [4:0] PG12MFP — PG.12 Multi-function Pin Selection
    2=EBI_AD3; 3=SD1_DAT0; 4=SPIM_CLK; 5=QSPI1_CLK; 6=UART7_RXD; 7=CCAP_VSYNC; 8=I2C4_SMBSUS; 12=BPWM0_CH2; 16=HBI_D1; 19=SPI8_MISO
0x570 SYS_GPH_MFP0 — GPIOH Multiple Function Control Register 0
  [28:24] PH3MFP — PH.3 Multi-function Pin Selection
    2=EBI_ADR4; 3=SPI1_I2SMCLK; 4=UART5_nCTS; 5=UART4_RXD; 6=I2C0_SDA; 13=TM3_EXT
  [20:16] PH2MFP — PH.2 Multi-function Pin Selection
    2=EBI_ADR5; 4=UART5_nRTS; 5=UART4_TXD; 6=I2C0_SCL; 13=TM2_EXT
  [12:8] PH1MFP — PH.1 Multi-function Pin Selection
    2=EBI_ADR6; 4=UART5_RXD; 13=TM1_EXT
  [4:0] PH0MFP — PH.0 Multi-function Pin Selection
    2=EBI_ADR7; 4=UART5_TXD; 13=TM0_EXT
0x574 SYS_GPH_MFP1 — GPIOH Multiple Function Control Register 1
  [28:24] PH7MFP — PH.7 Multi-function Pin Selection
    2=EBI_ADR0; 3=SPI1_SS; 4=UART7_RXD; 7=UART9_nRTS
  [20:16] PH6MFP — PH.6 Multi-function Pin Selection
    2=EBI_ADR1; 3=SPI1_CLK; 4=UART7_TXD; 7=UART9_nCTS
  [12:8] PH5MFP — PH.5 Multi-function Pin Selection
    2=EBI_ADR2; 3=SPI1_MOSI; 4=UART7_nCTS; 5=UART6_RXD
  [4:0] PH4MFP — PH.4 Multi-function Pin Selection
    2=EBI_ADR3; 3=SPI1_MISO; 4=UART7_nRTS; 5=UART6_TXD
0x578 SYS_GPH_MFP2 — GPIOH Multiple Function Control Register 2
  [28:24] PH11MFP — PH.11 Multi-function Pin Selection
    2=EBI_AD15; 3=QSPI0_MOSI1; 7=UART4_RXD; 8=UART0_RXD; 11=EPWM0_CH5; 13=UART9_RXD
  [20:16] PH10MFP — PH.10 Multi-function Pin Selection
    2=EBI_AD14; 3=QSPI0_MISO1; 4=SC2_nCD; 5=I2S0_LRCK; 6=SPI1_I2SMCLK; 7=UART4_TXD; 8=UART0_TXD; 13=UART9_TXD
  [12:8] PH9MFP — PH.9 Multi-function Pin Selection
    2=EBI_AD13; 3=QSPI0_SS; 4=SC2_RST; 5=I2S0_DO; 6=SPI1_SS; 7=UART3_nCTS; 8=I2C1_SMBSUS; 9=I2C2_SDA; 10=UART1_RXD; 13=UART9_nRTS
  [4:0] PH8MFP — PH.8 Multi-function Pin Selection
    2=EBI_AD12; 3=QSPI0_CLK; 4=SC2_PWR; 5=I2S0_DI; 6=SPI1_CLK; 7=UART3_nRTS; 8=I2C1_SMBAL; 9=I2C2_SCL; 10=UART1_TXD; 13=UART9_nCTS
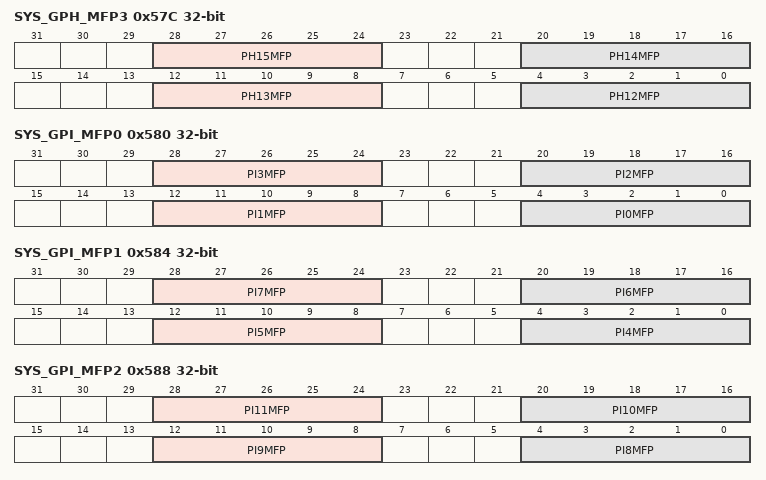
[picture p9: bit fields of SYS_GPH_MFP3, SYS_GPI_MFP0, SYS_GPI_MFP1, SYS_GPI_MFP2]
0x57C SYS_GPH_MFP3 — GPIOH Multiple Function Control Register 3
  [28:24] PH15MFP — PH.15 Multi-function Pin Selection
    2=EBI_AD3; 6=QSPI1_CLK; 7=CCAP_VSYNC; 16=HBI_D4
  [20:16] PH14MFP — PH.14 Multi-function Pin Selection
    2=EBI_AD2; 6=QSPI1_SS; 7=CCAP_SFIELD; 16=HBI_RWDS
  [12:8] PH13MFP — PH.13 Multi-function Pin Selection
    2=EBI_AD1; 3=UART9_RXD; 6=QSPI1_MOSI1; 7=CCAP_SCLK; 10=CAN3_RXD; 16=HBI_CK
  [4:0] PH12MFP — PH.12 Multi-function Pin Selection
    2=EBI_AD0; 3=UART9_TXD; 6=QSPI1_MISO1; 7=CCAP_PIXCLK; 10=CAN3_TXD; 16=HBI_nCK
0x580 SYS_GPI_MFP0 — GPIOI Multiple Function Control Register 0
  [28:24] PI3MFP — PI.3 Multi-function Pin Selection
  [20:16] PI2MFP — PI.2 Multi-function Pin Selection
  [12:8] PI1MFP — PI.1 Multi-function Pin Selection
  [4:0] PI0MFP — PI.0 Multi-function Pin Selection
0x584 SYS_GPI_MFP1 — GPIOI Multiple Function Control Register 1
  [28:24] PI7MFP — PI.7 Multi-function Pin Selection
    5=SC1_PWR; 6=I2S0_MCLK; 7=SPI1_MISO; 8=UART2_RXD; 9=I2C1_SDA; 13=CAN3_RXD; 15=USB_VBUS_EN
  [20:16] PI6MFP — PI.6 Multi-function Pin Selection
    5=SC1_nCD; 6=I2S0_BCLK; 7=SPI1_I2SMCLK; 8=UART2_TXD; 9=I2C1_SCL; 13=CAN3_TXD; 15=USB_VBUS_ST
  [12:8] PI5MFP — PI.5 Multi-function Pin Selection
  [4:0] PI4MFP — PI.4 Multi-function Pin Selection
0x588 SYS_GPI_MFP2 — GPIOI Multiple Function Control Register 2
  [28:24] PI11MFP — PI.11 Multi-function Pin Selection
    8=UART2_RXD; 9=I2C0_SDA; 13=CAN3_RXD
  [20:16] PI10MFP — PI.10 Multi-function Pin Selection
    5=SC1_CLK; 6=I2S0_LRCK; 7=SPI1_SS; 8=UART2_TXD; 9=I2C0_SCL; 13=CAN3_TXD
  [12:8] PI9MFP — PI.9 Multi-function Pin Selection
    5=SC1_DAT; 6=I2S0_DO; 7=SPI1_CLK; 8=UART2_nCTS; 9=I2C0_SMBSUS; 13=CAN2_RXD
  [4:0] PI8MFP — PI.8 Multi-function Pin Selection
    5=SC1_RST; 6=I2S0_DI; 7=SPI1_MOSI; 8=UART2_nRTS; 9=I2C0_SMBAL; 13=CAN2_TXD
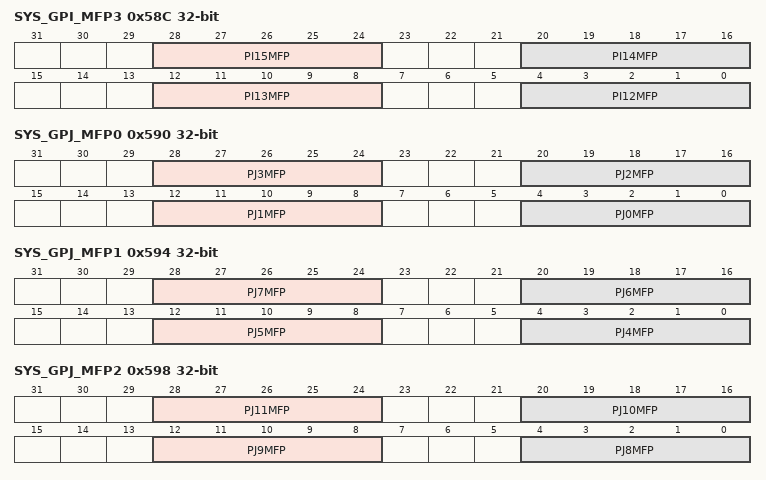
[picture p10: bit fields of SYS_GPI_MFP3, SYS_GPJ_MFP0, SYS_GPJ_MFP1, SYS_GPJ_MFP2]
0x58C SYS_GPI_MFP3 — GPIOI Multiple Function Control Register 3
  [28:24] PI15MFP — PI.15 Multi-function Pin Selection
    3=SPIM_D3; 4=QSPI0_CLK; 7=UART8_nRTS; 10=CAN1_RXD; 11=UART3_RXD; 12=EPWM1_CH3; 15=I2C3_SDA
  [20:16] PI14MFP — PI.14 Multi-function Pin Selection
    3=SPIM_D2; 4=QSPI0_SS; 7=UART8_nCTS; 10=CAN1_TXD; 11=UART3_TXD; 12=EPWM1_CH2; 15=I2C3_SCL
  [12:8] PI13MFP — PI.13 Multi-function Pin Selection
    3=SPIM_MISO; 4=QSPI0_MOSI1; 10=CAN0_RXD; 11=UART4_RXD; 12=EPWM1_CH1; 15=I2C3_SMBSUS
  [4:0] PI12MFP — PI.12 Multi-function Pin Selection
    3=SPIM_SS; 4=QSPI0_MISO1; 10=CAN0_TXD; 11=UART4_TXD; 12=EPWM1_CH0; 15=I2C3_SMBAL
0x590 SYS_GPJ_MFP0 — GPIOJ Multiple Function Control Register 0
  [28:24] PJ3MFP — PJ.3 Multi-function Pin Selection
    2=EBI_AD4; 3=UART8_nRTS; 6=QSPI1_CLK; 7=CCAP_DATA4; 10=CAN0_RXD; 16=HBI_D3
  [20:16] PJ2MFP — PJ.2 Multi-function Pin Selection
    2=EBI_AD5; 3=UART8_nCTS; 6=QSPI1_SS; 7=CCAP_DATA5; 10=CAN0_TXD; 16=HBI_nRESET
  [12:8] PJ1MFP — PJ.1 Multi-function Pin Selection
    3=SPIM_MOSI; 4=QSPI0_MOSI0; 7=UART8_RXD; 10=CAN2_RXD; 12=EPWM1_CH5
  [4:0] PJ0MFP — PJ.0 Multi-function Pin Selection
    3=SPIM_CLK; 4=QSPI0_MISO0; 7=UART8_TXD; 10=CAN2_TXD; 12=EPWM1_CH4
0x594 SYS_GPJ_MFP1 — GPIOJ Multiple Function Control Register 1
  [28:24] PJ7MFP — PJ.7 Multi-function Pin Selection
    2=EBI_AD0; 3=UART9_nRTS; 7=CCAP_DATA0; 10=CAN2_RXD; 16=HBI_nCS
  [20:16] PJ6MFP — PJ.6 Multi-function Pin Selection
    2=EBI_AD1; 3=UART9_nCTS; 7=CCAP_DATA1; 10=CAN2_TXD; 16=HBI_D0
  [12:8] PJ5MFP — PJ.5 Multi-function Pin Selection
    2=EBI_AD2; 3=UART8_RXD; 6=QSPI1_MOSI0; 7=CCAP_DATA2; 10=CAN1_RXD; 16=HBI_D1
  [4:0] PJ4MFP — PJ.4 Multi-function Pin Selection
    2=EBI_AD3; 3=UART8_TXD; 6=QSPI1_MISO0; 7=CCAP_DATA3; 10=CAN1_TXD; 16=HBI_D2
0x598 SYS_GPJ_MFP2 — GPIOJ Multiple Function Control Register 2
  [28:24] PJ11MFP — PJ.11 Multi-function Pin Selection
    2=EBI_ALE; 3=SD1_DAT0; 4=SPIM_D3; 6=UART6_RXD; 8=I2C4_SDA; 9=ECAP2_IC1; 11=CAN0_RXD; 12=BPWM0_CH2
  [20:16] PJ10MFP — PJ.10 Multi-function Pin Selection
    2=EBI_MCLK; 3=SD1_DAT1; 4=SPIM_D2; 6=UART6_TXD; 8=I2C4_SCL; 9=ECAP2_IC0; 11=CAN0_TXD; 12=BPWM0_CH3
  [12:8] PJ9MFP — PJ.9 Multi-function Pin Selection
    2=EBI_nWR; 3=SD1_DAT2; 4=SPIM_MISO; 6=UART7_RXD; 11=CAN2_RXD; 12=BPWM0_CH4
  [4:0] PJ8MFP — PJ.8 Multi-function Pin Selection
    2=EBI_nRD; 3=SD1_DAT3; 4=SPIM_SS; 6=UART7_TXD; 11=CAN2_TXD; 12=BPWM0_CH5
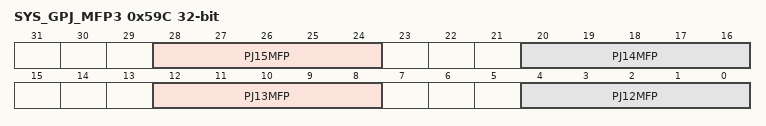
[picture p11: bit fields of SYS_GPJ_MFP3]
0x59C SYS_GPJ_MFP3 — GPIOJ Multiple Function Control Register 3
  [28:24] PJ15MFP — PJ.15 Multi-function Pin Selection
  [20:16] PJ14MFP — PJ.14 Multi-function Pin Selection
  [12:8] PJ13MFP — PJ.13 Multi-function Pin Selection
    3=SD1_CLK; 4=SPIM_MOSI; 8=I2C4_SMBSUS; 11=CAN1_RXD; 12=BPWM0_CH0; 15=HSUSB_VBUS_EN
  [4:0] PJ12MFP — PJ.12 Multi-function Pin Selection
    2=EBI_nCS0; 3=SD1_CMD; 4=SPIM_CLK; 8=I2C4_SMBAL; 9=ECAP2_IC2; 11=CAN1_TXD; 12=BPWM0_CH1; 15=HSUSB_VBUS_ST
